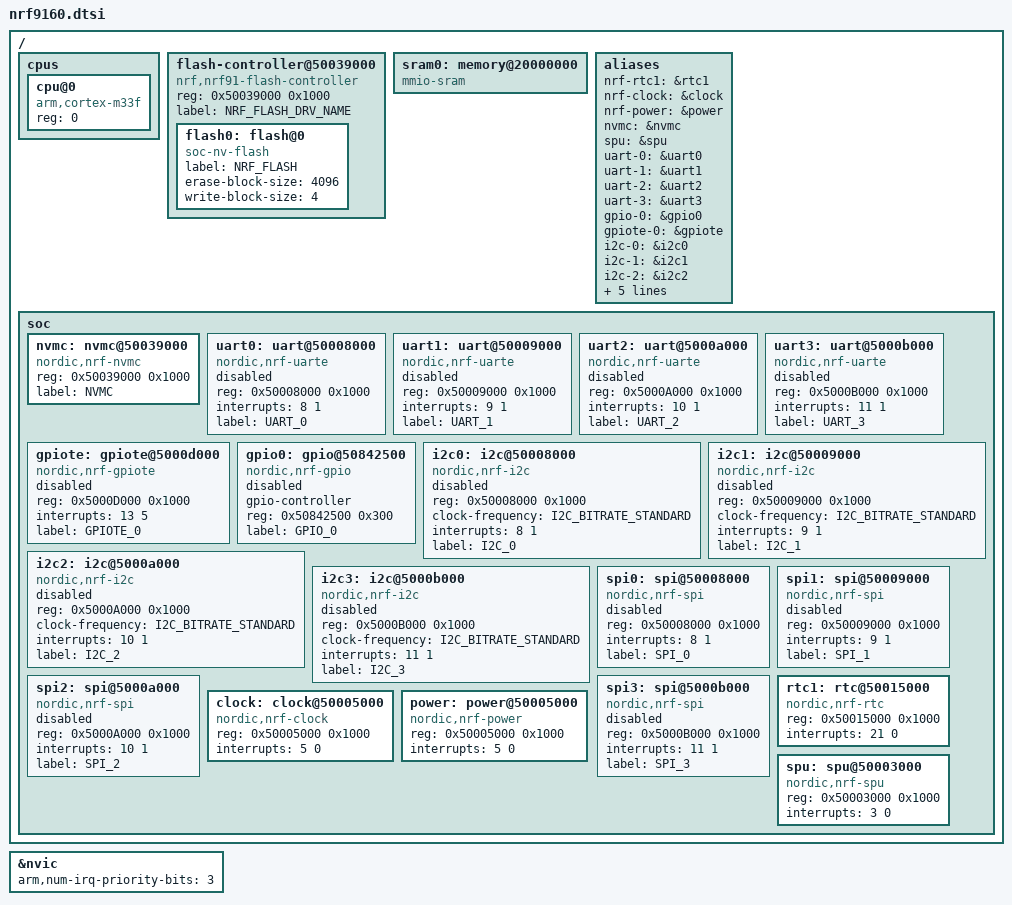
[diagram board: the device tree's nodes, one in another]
#include <arm/armv8-m.dtsi>
#include <dt-bindings/i2c/i2c.h>
#include <dt-bindings/gpio/gpio.h>

/ {
	cpus {
		#address-cells = <1>;
		#size-cells = <0>;

		cpu@0 {
			device_type = "cpu";
			compatible = "arm,cortex-m33f";
			reg = <0>;
		};
	};

	flash-controller@50039000 {
			compatible = "nrf,nrf91-flash-controller";
			reg = <0x50039000 0x1000>;

			#address-cells = <1>;
			#size-cells = <1>;

			label="NRF_FLASH_DRV_NAME";

			flash0: flash@0 {
				compatible = "soc-nv-flash";
				label = "NRF_FLASH";
				erase-block-size = <4096>;
				write-block-size = <4>;
			};
	};

	sram0: memory@20000000 {
		device_type = "memory";
		compatible = "mmio-sram";
	};

	aliases {
		nrf-rtc1 = &rtc1;
		nrf-clock = &clock;
		nrf-power = &power;
		nvmc = &nvmc;
		spu = &spu;
		uart-0 = &uart0;
		uart-1 = &uart1;
		uart-2 = &uart2;
		uart-3 = &uart3;
		gpio-0 = &gpio0;
		gpiote-0 = &gpiote;
		i2c-0 = &i2c0;
		i2c-1 = &i2c1;
		i2c-2 = &i2c2;
		i2c-3 = &i2c3;
		spi-0 = &spi0;
		spi-1 = &spi1;
		spi-2 = &spi2;
		spi-3 = &spi3;
	};

	soc {
		nvmc: nvmc@50039000 {
			compatible = "nordic,nrf-nvmc";
			reg = <0x50039000 0x1000>;
			status = "ok";
			label = "NVMC";
		};

		uart0: uart@50008000 {
			compatible = "nordic,nrf-uarte";
			reg = <0x50008000 0x1000>;
			interrupts = <8 1>;
			status = "disabled";
			label = "UART_0";
		};

		uart1: uart@50009000 {
			compatible = "nordic,nrf-uarte";
			reg = <0x50009000 0x1000>;
			interrupts = <9 1>;
			status = "disabled";
			label = "UART_1";
		};

		uart2: uart@5000a000 {
			compatible = "nordic,nrf-uarte";
			reg = <0x5000A000 0x1000>;
			interrupts = <10 1>;
			status = "disabled";
			label = "UART_2";
		};

		uart3: uart@5000b000 {
			compatible = "nordic,nrf-uarte";
			reg = <0x5000B000 0x1000>;
			interrupts = <11 1>;
			status = "disabled";
			label = "UART_3";
		};

		gpiote: gpiote@5000d000 {
			compatible = "nordic,nrf-gpiote";
			reg = <0x5000D000 0x1000>;
			interrupts = <13 5>;
			status = "disabled";
			label = "GPIOTE_0";
		};

		gpio0: gpio@50842500 {
			compatible = "nordic,nrf-gpio";
			gpio-controller;
			reg = <0x50842500 0x300>;
			#gpio-cells = <2>;
			label = "GPIO_0";
			status = "disabled";
		};

		i2c0: i2c@50008000 {
			compatible = "nordic,nrf-i2c";
			#address-cells = <1>;
			#size-cells = <0>;
			reg = <0x50008000 0x1000>;
			clock-frequency = <I2C_BITRATE_STANDARD>;
			interrupts = <8 1>;
			status = "disabled";
			label = "I2C_0";
		};

		i2c1: i2c@50009000 {
			compatible = "nordic,nrf-i2c";
			#address-cells = <1>;
			#size-cells = <0>;
			reg = <0x50009000 0x1000>;
			clock-frequency = <I2C_BITRATE_STANDARD>;
			interrupts = <9 1>;
			status = "disabled";
			label = "I2C_1";
		};

		i2c2: i2c@5000a000 {
			compatible = "nordic,nrf-i2c";
			#address-cells = <1>;
			#size-cells = <0>;
			reg = <0x5000A000 0x1000>;
			clock-frequency = <I2C_BITRATE_STANDARD>;
			interrupts = <10 1>;
			status = "disabled";
			label = "I2C_2";
		};

		i2c3: i2c@5000b000 {
			compatible = "nordic,nrf-i2c";
			#address-cells = <1>;
			#size-cells = <0>;
			reg = <0x5000B000 0x1000>;
			clock-frequency = <I2C_BITRATE_STANDARD>;
			interrupts = <11 1>;
			status = "disabled";
			label = "I2C_3";
		};

		spi0: spi@50008000 {
			compatible = "nordic,nrf-spi";
			#address-cells = <1>;
			#size-cells = <0>;
			reg = <0x50008000 0x1000>;
			interrupts = <8 1>;
			status = "disabled";
			label = "SPI_0";
		};

		spi1: spi@50009000 {
			compatible = "nordic,nrf-spi";
			#address-cells = <1>;
			#size-cells = <0>;
			reg = <0x50009000 0x1000>;
			interrupts = <9 1>;
			status = "disabled";
			label = "SPI_1";
		};

		spi2: spi@5000a000 {
			compatible = "nordic,nrf-spi";
			#address-cells = <1>;
			#size-cells = <0>;
			reg = <0x5000A000 0x1000>;
			interrupts = <10 1>;
			status = "disabled";
			label = "SPI_2";
		};

		spi3: spi@5000b000 {
			compatible = "nordic,nrf-spi";
			#address-cells = <1>;
			#size-cells = <0>;
			reg = <0x5000B000 0x1000>;
			interrupts = <11 1>;
			status = "disabled";
			label = "SPI_3";
		};

		rtc1: rtc@50015000 {
			compatible = "nordic,nrf-rtc";
			reg = <0x50015000 0x1000>;
			interrupts = <21 0>;
			status = "ok";
		};

		clock: clock@50005000 {
			compatible = "nordic,nrf-clock";
			reg = <0x50005000 0x1000>;
			interrupts = <5 0>;
			status = "ok";
		};

		power: power@50005000 {
			compatible = "nordic,nrf-power";
			reg = <0x50005000 0x1000>;
			interrupts = <5 0>;
			status = "ok";
		};

		spu: spu@50003000 {
			compatible = "nordic,nrf-spu";
			reg = <0x50003000 0x1000>;
			interrupts = <3 0>;
			status = "ok";
		};
	};
};

&nvic {
	arm,num-irq-priority-bits = <3>;
};
